# ESP32-C6 register map
Vendor: ESPRESSIF SYSTEMS (SHANGHAI) CO., LTD.; Series: ESP32 C-Series; File version: 12
CPU: RV32IMAC r0p0, little endian, no MPU, no FPU, 0 interrupt priority bits
Address unit: 32 bits
Registers are 32-bit, read-write, reset 0x0 unless marked. A register's access mark holds for its fields unless they carry their own. Offsets are from the block's base; [hi:lo] are bit positions; {n}, {i} and the like mark numbered series.

## CLINT — Core Local Interrupts
Base 0x20000000
0x1800 MSIP — Core-local machine software interrupt pending register
  [0] MSIP — Configures the pending status of the machine software interrupt.
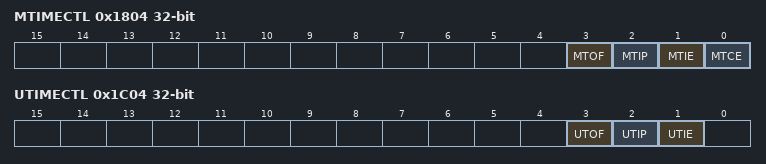
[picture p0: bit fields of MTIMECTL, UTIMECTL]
0x1804 MTIMECTL access per field — Core-local machine timer interrupt control/status register
  [3] MTOF rw — Configures whether the machine timer overflows.
  [2] MTIP ro — Represents the pending status of the machine timer interrupt.
  [1] MTIE rw — Write 1 to enable the machine timer interrupt.
  [0] MTCE rw — Configures whether to enable the CLINT timer counter.
0x1808 MTIME 64-bit (reset mask 0xFFFFFFFF) — Core-local system counter value
  [63:0] MTIME — Configures the 64-bit CLINT timer counter value.
0x1810 MTIMECMP 64-bit (reset mask 0xFFFFFFFF) — Core-local machine timer compare value
  [63:0] MTIMECMP — Configures the 64-bit machine timer compare value.
0x1C00 USIP — Core-local user software interrupt pending register
  [0] USIP — Configures the pending status of the user software interrupt.
0x1C04 UTIMECTL access per field — Core-local user timer interrupt control/status register
  [3] UTOF rw — Configures whether the user timer overflows.
  [2] UTIP ro — Represents the pending status of the user timer interrupt.
  [1] UTIE rw — Write 1 to enable the user timer interrupt.
0x1C08 UTIME 64-bit ro (reset mask 0xFFFFFFFF) — Read-only 64-bit core local timer counter value
  [63:0] UTIME — Represents the read-only 64-bit CLINT timer counter value.
0x1C10 UTIMECMP 64-bit (reset mask 0xFFFFFFFF) — Core-local user timer compare value
  [63:0] UTIMECMP — Configures the 64-bit user timer compare value.

## PLIC_MX — PLIC Peripheral
Base 0x20001000
0x00 MXINT_ENABLE — PLIC MX Interrupt Enable Register
  [31:0] CPU_MXINT_ENABLE
0x04 MXINT_TYPE — PLIC MX Interrupt Type Register
  [31:0] CPU_MXINT_TYPE
0x08 MXINT_CLEAR — PLIC MX Interrupt Clear Register
  [31:0] CPU_MXINT_CLEAR
0x0C EMIP_STATUS ro — PLIC EMIP Status Register
  [31:0] CPU_EIP_STATUS
{0x10+4i} MXINT{i}_PRI (i=0..31) — PLIC MX Interrupt {i} Priority Register
  [3:0] CPU_MXINT_PRI
0x90 MXINT_THRESH — PLIC MX Interrupt Threshold Register
  [7:0] CPU_MXINT_THRESH
0x94 MXINT_CLAIM — PLIC MX Interrupt Claim Register
  [31:0] CPU_MXINT_CLAIM — hp_mb_int is generated after writing 32'h20200721 to core0_lp_intr_flag.
0x3FC MXINT_CONF — PLIC MX Interrupt Configuration Register (PLIC_MXINT_CONF_REG)
  [31:0] CPU_MXINT_CONF

## PLIC_UX — PLIC Peripheral
Base 0x20001400
0x00 UXINT_ENABLE — PLIC UX Interrupt Enable Register
  [31:0] CPU_UXINT_ENABLE
0x04 UXINT_TYPE — PLIC UX Interrupt Type Register
  [31:0] CPU_UXINT_TYPE
0x08 UXINT_CLEAR — PLIC UX Interrupt Clear Register
  [31:0] CPU_UXINT_CLEAR
0x0C EUIP_STATUS ro — PLIC EMIP Status Register
  [31:0] CPU_EIP_STATUS
{0x10+4i} UXINT{i}_PRI (i=0..31) — PLIC UX Interrupt {i} Priority Register
  [3:0] CPU_UXINT_PRI
0x90 UXINT_THRESH — PLIC UX Interrupt Threshold Register
  [7:0] CPU_UXINT_THRESH
0x94 UXINT_CLAIM — PLIC UX Interrupt Claim Register
  [31:0] CPU_UXINT_CLAIM — hp_mb_int is generated after writing 32'h20200721 to core0_lp_intr_flag.
0x3FC UXINT_CONF — PLIC UX Interrupt Configuration Register (PLIC_UXINT_CONF_REG)
  [31:0] CPU_UXINT_CONF

## AES — AES (Advanced Encryption Standard) Accelerator
Base 0x60088000
{0x0+4i} KEY{i} (i=0..7) — Key material key_{i} configure register
  [31:0] KEY — This bits stores key_0 that is a part of key material.
{0x20+4i} TEXT_IN{i} (i=0..3) — source text material text_in_{i} configure register
  [31:0] TEXT_IN — This bits stores text_in_0 that is a part of source text material.
{0x30+4i} TEXT_OUT{i} (i=0..3) — result text material text_out_{i} configure register
  [31:0] TEXT_OUT — This bits stores text_out_0 that is a part of result text material.
0x40 MODE — AES Mode register
  [2:0] MODE — This bits decides which one operation mode will be used. 3'd0: AES-EN-128, 3'd1: AES-EN-192, 3'd2: AES-EN-256, 3'd4: AES-DE-128, 3'd5: AES-DE-192, 3'd6: AES-DE-256.
0x44 ENDIAN — AES Endian configure register
  [5:0] ENDIAN — endian. [1:0] key endian, [3:2] text_in endian or in_stream endian, [5:4] text_out endian or out_stream endian
0x48 TRIGGER wo — AES trigger register
  [0] TRIGGER — Set this bit to start AES calculation.
0x4C STATE ro — AES state register
  [1:0] STATE — Those bits shows AES status. For typical AES, 0: idle, 1: busy. For DMA-AES, 0: idle, 1: busy, 2: calculation_done.
{0x50+4i} IV_MEM[{i}] (i=0..3) access not given — The memory that stores initialization vector
{0x60+4i} H_MEM[{i}] (i=0..3) access not given — The memory that stores GCM hash subkey
{0x70+4i} J0_MEM[{i}] (i=0..3) access not given — The memory that stores J0
{0x80+4i} T0_MEM[{i}] (i=0..3) access not given — The memory that stores T0
0x90 DMA_ENABLE — DMA-AES working mode register
  [0] DMA_ENABLE — 1'b0: typical AES working mode, 1'b1: DMA-AES working mode.
0x94 BLOCK_MODE — AES cipher block mode register
  [2:0] BLOCK_MODE — Those bits decides which block mode will be used. 0x0: ECB, 0x1: CBC, 0x2: OFB, 0x3: CTR, 0x4: CFB-8, 0x5: CFB-128, 0x6: GCM, 0x7: reserved.
0x98 BLOCK_NUM — AES block number register
  [31:0] BLOCK_NUM — Those bits stores the number of Plaintext/ciphertext block.
0x9C INC_SEL — Standard incrementing function configure register
  [0] INC_SEL — This bit decides the standard incrementing function. 0: INC32. 1: INC128.
0xA0 AAD_BLOCK_NUM — Additional Authential Data block number register
  [31:0] AAD_BLOCK_NUM — Those bits stores the number of AAD block.
0xA4 REMAINDER_BIT_NUM — AES remainder bit number register
  [6:0] REMAINDER_BIT_NUM — Those bits stores the number of remainder bit.
0xA8 CONTINUE wo — AES continue register
  [0] CONTINUE — Set this bit to continue GCM operation.
0xAC INT_CLR wo — AES Interrupt clear register
  [0] INT_CLR — Set this bit to clear the AES interrupt.
0xB0 INT_ENA — AES Interrupt enable register
  [0] INT_ENA — Set this bit to enable interrupt that occurs when DMA-AES calculation is done.
0xB4 DATE — AES version control register
0xB8 DMA_EXIT wo — AES-DMA exit config
  [0] DMA_EXIT — Set this register to leave calculation done stage. Recommend to use it after software finishes reading DMA's output buffer.
